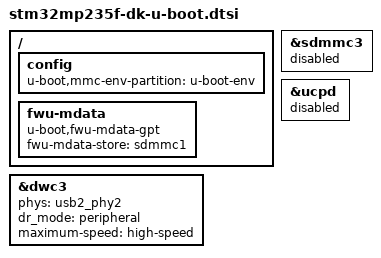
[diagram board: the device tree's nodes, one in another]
// SPDX-License-Identifier: GPL-2.0-or-later OR BSD-3-Clause
/*
 * Copyright (C) STMicroelectronics 2024 - All Rights Reserved
 */

#include "stm32mp23-u-boot.dtsi"

/ {
	config {
		u-boot,mmc-env-partition = "u-boot-env";
	};

	fwu-mdata {
		compatible = "u-boot,fwu-mdata-gpt";
		fwu-mdata-store = <&sdmmc1>;
	};
};

&dwc3 {
	phys = <&usb2_phy2>;
	phy-names = "usb2-phy";
	dr_mode = "peripheral";
	maximum-speed = "high-speed";
	/delete-node/ port;
};

&sdmmc3 {
	status = "disabled";
};

&ucpd {
	status = "disabled";
	/delete-node/ connector;
};
